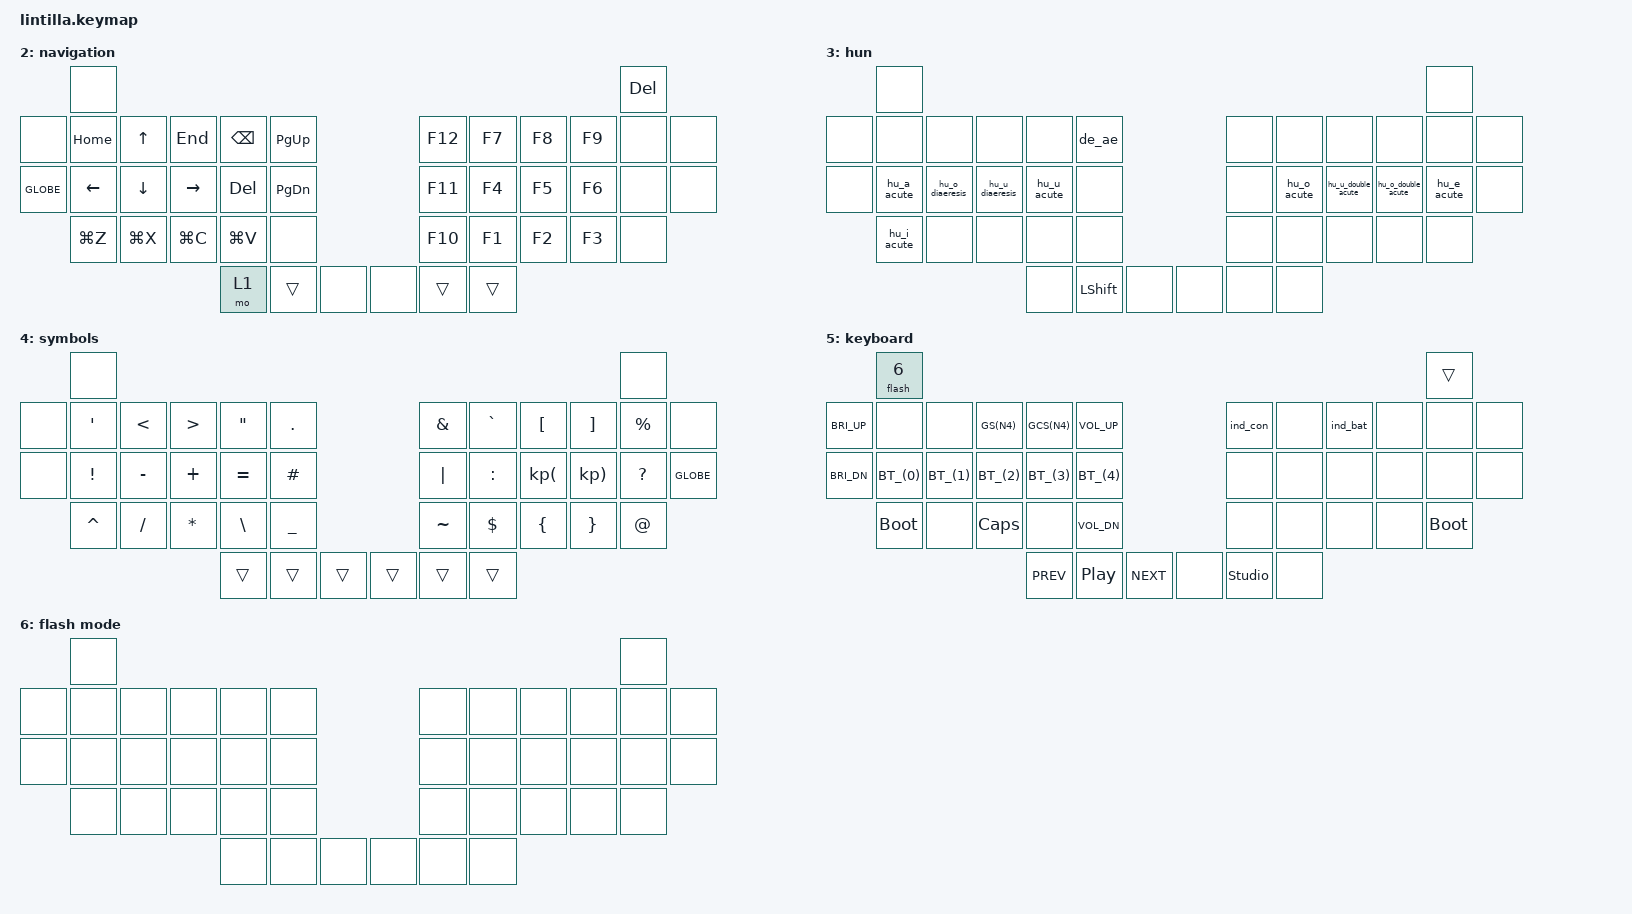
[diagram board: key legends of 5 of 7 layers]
#include <behaviors.dtsi>
#include <dt-bindings/zmk/bt.h>
#include <dt-bindings/zmk/keys.h>
#include <dt-bindings/zmk/outputs.h>
#include <behaviors/rgbled_widget.dtsi>

#include "lintilla_combos.dtsi"
#define HOST_OS 1
#include "zmk-helpers/helper.h"

#include "zmk-helpers/unicode-chars/german.dtsi"


// Multiple mods
#define GS(key) &kp LG(LS(key))
#define GCS(key) &kp LG(LC(LS(key)))
#define HYPR(key) &kp LG(LA(LC(LS(key))))

// Shortcuts for home row mods
#define LGlb &hml GLOBE
#define LSft &hml LSHFT
#define LCtl &hml LCTRL
#define Opt  &hml LALT
#define LCmd &hml LGUI

#define RGlb &hmr GLOBE
#define RSft &hmr LSHFT
#define RCtl &hmr LCTRL
#define RCmd &hmr LGUI
#define Alt  &hmr RALT

ZMK_UNICODE_PAIR(hu_a_acute,        N0, N0,  E, N1,  N0, N0,  C, N1) // á/Á
ZMK_UNICODE_PAIR(hu_e_acute,        N0, N0,  E, N9,  N0, N0,  C, N9) // é/É
ZMK_UNICODE_PAIR(hu_i_acute,        N0, N0,  E,  D,  N0, N0,  C,  D) // í/Í
ZMK_UNICODE_PAIR(hu_o_acute,        N0, N0,  F, N3,  N0, N0,  D, N3) // ó/Ó
ZMK_UNICODE_PAIR(hu_o_diaeresis,    N0, N0,  F, N6,  N0, N0,  D, N6) // ö/Ö
ZMK_UNICODE_PAIR(hu_o_double_acute, N0, N1, N5, N1,  N0, N1, N5, N0) // ő/Ő
ZMK_UNICODE_PAIR(hu_u_acute,        N0, N0,  F,  A,  N0, N0,  D,  A) // ú/Ú
ZMK_UNICODE_PAIR(hu_u_diaeresis,    N0, N0,  F,  C,  N0, N0,  D,  C) // ü/Ü
ZMK_UNICODE_PAIR(hu_u_double_acute, N0, N1, N7, N1,  N0, N1, N7, N0) // ű/Ű

#define KEYS_L 0 2 3  4  5  6  7 14 15 16 17 18 19 26 27 28 29 30
#define KEYS_R 1 8 9 10 11 12 13 20 21 22 23 24 25 31 32 33 34 35
#define THUMBS 36 37 38 39 40 41

// Magic bluetooth button
#define BT_(btnum) &bt_key btnum btnum

/ {
    behaviors {
        bt_key: magic_bluetooth_key {
            compatible = "zmk,behavior-hold-tap";
            #binding-cells = <2>;
            flavor = "tap-preferred";
            tapping-term-ms = <500>;
            bindings = <&bt_clr>, <&bt_sel>;
        };

        hml: homerow_mod_left {
            compatible = "zmk,behavior-hold-tap";
            #binding-cells = <2>;
            tapping-term-ms = <200>;
            require-prior-idle-ms = <150>;
            quick-tap-ms = <175>;
            flavor = "balanced";
            hold-trigger-key-positions = <KEYS_R THUMBS>;
            hold-trigger-on-release;
            bindings = <&kp>, <&kp>;
        };

        hmr: homerow_mod_right {
            compatible = "zmk,behavior-hold-tap";
            #binding-cells = <2>;
            tapping-term-ms = <200>;
            require-prior-idle-ms = <150>;
            quick-tap-ms = <175>;
            flavor = "balanced";
            hold-trigger-key-positions = <KEYS_L THUMBS>;
            hold-trigger-on-release;
            bindings = <&kp>, <&kp>;
        };

        lp_mc: launch_pad_mission_control {
            compatible = "zmk,behavior-tap-dance";
            #binding-cells = <0>;
            tapping-term-ms = <200>;
            bindings = <HYPR(N4)>, <&kp LC(UP)>;
        };

        lsscw: layer_sticky_shift_caps_word {
            compatible = "zmk,behavior-hold-tap";
            #binding-cells = <2>;
            flavor = "balanced";
            tapping-term-ms = <200>;
            bindings = <&mo>, <&sscw>;
        };

        mcs: mod_comma_semi {
            compatible = "zmk,behavior-mod-morph";
            #binding-cells = <0>;
            bindings = <&kp COMMA>, <&kp SEMI>;
            mods = <(MOD_LSFT|MOD_RSFT)>;
        };

        mdc: mod_dot_colon {
            compatible = "zmk,behavior-mod-morph";
            #binding-cells = <0>;
            bindings = <&kp DOT>, <&kp COLON>;
            mods = <(MOD_LSFT|MOD_RSFT)>;
        };

        msb: mod_slash_back {
            compatible = "zmk,behavior-mod-morph";
            #binding-cells = <0>;
            bindings = <&kp SLASH>, <&kp BACKSLASH>;
            mods = <(MOD_LSFT|MOD_RSFT)>;
        };

        sscw: sticky_shift_caps_word {
            compatible = "zmk,behavior-mod-morph";
            #binding-cells = <0>;
            bindings = <&sk LSHIFT>, <&caps_word>;
            mods = <(MOD_LSFT|MOD_RSFT)>;
        };
    };

    macros {
        bt_clr: bluetooth_clear {
            compatible = "zmk,behavior-macro-one-param";
            #binding-cells = <1>;
            bindings = <&macro_param_1to1 &bt_sel MACRO_PLACEHOLDER>, <&bt BT_CLR>;
        };

        bt_sel: bluetooth_select {
            compatible = "zmk,behavior-macro-one-param";
            #binding-cells = <1>;
            bindings = <&out OUT_BLE>, <&macro_param_1to2 &bt BT_SEL MACRO_PLACEHOLDER>;
        };

        flash: dongle_bootloader {
            compatible = "zmk,behavior-macro-one-param";
            #binding-cells = <1>;
            bindings = <&macro_param_1to1 &to MACRO_PLACEHOLDER>, <&bootloader>;
        };

        tmsw: tmux_switch {
            compatible = "zmk,behavior-macro-one-param";
            #binding-cells = <1>;
            bindings = <&kp LC(B) &macro_param_1to1 &kp MACRO_PLACEHOLDER>;
        };
    };



    keymap {
        compatible = "zmk,keymap";

        qwerty {
//                       ┏━━━━━━━━━━━━━━━━━━━━━━━━━┓
            display-name = "Qwerty"                ; // 0
//                       ┗━━━━━━━━━━━━━━━━━━━━━━━━━┛
            bindings = <
//         ┏━━━━━━━┓                                                                                          ┏━━━━━━━┓
//         ┃LAUNCHP┃                                                                                          ┃ MUTE  ┃
            &lp_mc                                                                                          &lt 5 K_MUTE
//         ┃MISSION┃                                                                                          ┃ keybd ┃
// ┏━━━━━━━╋━━━━━━━╋━━━━━━━┳━━━━━━━┳━━━━━━━┳━━━━━━━┓                          ┏━━━━━━━┳━━━━━━━┳━━━━━━━┳━━━━━━━╋━━━━━━━╋━━━━━━━┓
// ┃ Repeat┃   Q   ┃   W   ┃   E   ┃   R   ┃   T   ┃                          ┃   Z   ┃   U   ┃   I   ┃   O   ┃   P   ┃  HUN  ┃
 &key_repeat &kp Q   &kp W   &kp E   &kp R   &kp T                              &kp Z   &kp U   &kp I   &kp O   &kp P   &sl 3
// ┣━━━━━━━╋━━━━━━━╋━━━━━━━╋━━━━━━━╋━━━━━━━╋━━━━━━━┫                          ┣━━━━━━━╋━━━━━━━╋━━━━━━━╋━━━━━━━╋━━━━━━━╋━━━━━━━┫
// ┃  TAB  ┃   A   ┃   S   ┃   D   ┃   F   ┃   G   ┃                          ┃   H   ┃   J   ┃   K   ┃   L   ┃  ; "  ┃RETURN ┃
  LGlb TAB  LCmd A   Opt S   LCtl D   LSft F  &kp G                            &kp H   RSft J   RCtl K   Alt L  RCmd SEMI &lt 3 RET
// ┃ Globe ┃  Cmd  ┃  Opt  ┃  Ctrl ┃ Shift ┃       ┃                          ┃ R Alt ┃ Shift ┃  Ctrl ┃ RAlt  ┃  Cmd  ┃ Globe ┃
// ┗━━━━━━━╋━━━━━━━╋━━━━━━━╋━━━━━━━╋━━━━━━━╋━━━━━━━┫                          ┣━━━━━━━╋━━━━━━━╋━━━━━━━╋━━━━━━━╋━━━━━━━╋━━━━━━━┛
//         ┃   Y   ┃   X   ┃   C   ┃   V   ┃   B   ┃                          ┃   N   ┃   M   ┃  , ;  ┃  . :  ┃  / \  ┃
             &kp Y   &kp X   &kp C   &kp V   &kp B                              &kp N   &kp M   &mcs    &mdc    &msb
//         ┗━━━━━━━┻━━━━━━━┻━━━━━━━┻━━━┳━━━┻━━━┳━━━┻━━━┳━━━━━━━┓  ┏━━━━━━━┳━━━┻━━━┳━━━┻━━━┳━━━┻━━━━━━━┻━━━━━━━┻━━━━━━━┛
//                                     ┃  ESC  ┃ SPACE ┃ { TAB ┃  ┃ } RET ┃ BKSPC ┃ StSft ┃
                                    &kp ESC &lt 4 SPC &lt 1 TAB   &lt 2 RET &kp BSPC &lsscw 3 0
//                                     ┗━━━━━━━┫  sym  ┣━━━━━━━┛  ┗━━━━━━━┫  sym  ┣━━━━━━━┛
//                                             ┗━━━━━━━┛                  ┗━━━━━━━┛
            >;
        };

        num {
//                       ┏━━━━━━━━━━━━━━━━━━━━━━━━━┓
            display-name = "numpad"                ; // 1
//                       ┗━━━━━━━━━━━━━━━━━━━━━━━━━┛
            bindings = <
//         ┏━━━━━━━┓                                                                                          ┏━━━━━━━┓
//         ┃       ┃                                                                                          ┃  DEL  ┃
             &none                                                                                             &kp DEL
// ┏━━━━━━━╋━━━━━━━╋━━━━━━━┳━━━━━━━┳━━━━━━━┳━━━━━━━┓                          ┏━━━━━━━┳━━━━━━━┳━━━━━━━┳━━━━━━━╋━━━━━━━╋━━━━━━━┓
// ┃       ┃       ┃       ┃       ┃       ┃       ┃                          ┃   /   ┃   7   ┃   8   ┃   9   ┃   -   ┃ BKSPC ┃
     &none   &none   &none   &none   &none   &none                            &kp SLASH &kp N7 &kp N8  &kp N9 &kp MINUS &kp BSPC
// ┣━━━━━━━╋━━━━━━━╋━━━━━━━╋━━━━━━━╋━━━━━━━╋━━━━━━━┫                          ┣━━━━━━━╋━━━━━━━╋━━━━━━━╋━━━━━━━╋━━━━━━━╋━━━━━━━┫
// ┃       ┃ CtrlA ┃       ┃ CtrlD ┃       ┃       ┃                          ┃   *   ┃   4   ┃   5   ┃   6   ┃   +   ┃RETURN ┃
&kp GLOBE  LCmd A   Opt S   LCtl D   LSft F  &trans                       &kp STAR &kp N4  &kp N5  &kp N6 &kp PLUS &kp RET
// ┃ Globe ┃ Shift ┃ Ctrl  ┃  Opt  ┃  Cmd  ┃       ┃                          ┃       ┃       ┃       ┃       ┃       ┃       ┃
// ┗━━━━━━━╋━━━━━━━╋━━━━━━━╋━━━━━━━╋━━━━━━━╋━━━━━━━┫                          ┣━━━━━━━╋━━━━━━━╋━━━━━━━╋━━━━━━━╋━━━━━━━╋━━━━━━━┛
//         ┃ CtrlZ ┃ CtrlX ┃ CtrlC ┃ CtrlV ┃       ┃                          ┃   :   ┃   1   ┃   2   ┃   3   ┃   0   ┃
         &kp LC(Z) &kp LC(X) &kp LC(C) &kp LC(V) &none                        &kp COLON &kp N1 &kp N2  &kp N3 &kp N0
//         ┗━━━━━━━┻━━━━━━━┻━━━━━━━┻━━━┳━━━┻━━━┳━━━┻━━━┳━━━━━━━┓  ┏━━━━━━━┳━━━┻━━━┳━━━┻━━━┳━━━┻━━━━━━━┻━━━━━━━┻━━━━━━━┛
//                                     ┃ ##### ┃       ┃       ┃  ┃   .   ┃ SPACE ┃   0   ┃
                                         &trans  &mo 2   &none    &kp COMMA &kp SPC &kp N0
//                                     ┗━━━━━━━┫  fn   ┣━━━━━━━┛  ┗━━━━━━━┫       ┣━━━━━━━┛
//                                             ┗━━━━━━━┛                  ┗━━━━━━━┛
            >;
        };

        nav {
//                       ┏━━━━━━━━━━━━━━━━━━━━━━━━━┓
            display-name = "navigation"            ; // 2
//                       ┗━━━━━━━━━━━━━━━━━━━━━━━━━┛
            bindings = <
//         ┏━━━━━━━┓                                                                                          ┏━━━━━━━┓
//         ┃       ┃                                                                                          ┃  DEL  ┃
             &none                                                                                             &kp DEL
// ┏━━━━━━━╋━━━━━━━╋━━━━━━━┳━━━━━━━┳━━━━━━━┳━━━━━━━┓                          ┏━━━━━━━┳━━━━━━━┳━━━━━━━┳━━━━━━━╋━━━━━━━╋━━━━━━━┓
// ┃       ┃ Home  ┃  Up   ┃  End  ┃ BKSPC ┃ Pg Up ┃                          ┃  F12  ┃  F7   ┃  F8   ┃  F9   ┃       ┃       ┃
     &none &kp HOME &kp UP &kp END &kp BSPC &kp PG_UP                          &kp F12  &kp F7  &kp F8  &kp F9  &none   &none
// ┣━━━━━━━╋━━━━━━━╋━━━━━━━╋━━━━━━━╋━━━━━━━╋━━━━━━━┫                          ┣━━━━━━━╋━━━━━━━╋━━━━━━━╋━━━━━━━╋━━━━━━━╋━━━━━━━┫
// ┃       ┃ Left  ┃ Down  ┃ Right ┃  DEL  ┃ Pg Dn ┃                          ┃  F11  ┃  F4   ┃  F5   ┃  F6   ┃       ┃       ┃
&kp GLOBE &kp LEFT &kp DOWN &kp RIGHT &kp DEL &kp PG_DN                        &kp F11  &kp F4  &kp F5  &kp F6  &none   &none
// ┃ Globe ┃       ┃       ┃       ┃       ┃       ┃                          ┃       ┃       ┃       ┃       ┃       ┃       ┃
// ┗━━━━━━━╋━━━━━━━╋━━━━━━━╋━━━━━━━╋━━━━━━━╋━━━━━━━┫                          ┣━━━━━━━╋━━━━━━━╋━━━━━━━╋━━━━━━━╋━━━━━━━╋━━━━━━━┛
//         ┃ Cmd Z ┃ Cmd X ┃ Cmd C ┃ Cmd V ┃       ┃                          ┃  F10  ┃  F1   ┃  F2   ┃  F3   ┃       ┃
         &kp LG(Z) &kp LG(X) &kp LG(C) &kp LG(V) &none                         &kp F10  &kp F1  &kp F2  &kp F3  &none
//         ┗━━━━━━━┻━━━━━━━┻━━━━━━━┻━━━┳━━━┻━━━┳━━━┻━━━┳━━━━━━━┓  ┏━━━━━━━┳━━━┻━━━┳━━━┻━━━┳━━━┻━━━━━━━┻━━━━━━━┻━━━━━━━┛
//                                     ┃  fn   ┃ ##### ┃       ┃  ┃       ┃ ##### ┃ ##### ┃
                                         &mo 1   &trans  &none      &none  &trans   &trans
//                                     ┗━━━━━━━┫       ┣━━━━━━━┛  ┗━━━━━━━┫       ┣━━━━━━━┛
//                                             ┗━━━━━━━┛                  ┗━━━━━━━┛
            >;
        };

        hun {
//                       ┏━━━━━━━━━━━━━━━━━━━━━━━━━┓
            display-name = "hun"                   ; // 3
//                       ┗━━━━━━━━━━━━━━━━━━━━━━━━━┛
            bindings = <
//         ┏━━━━━━━┓                                                                                          ┏━━━━━━━┓
//         ┃       ┃                                                                                          ┃       ┃
             &none                                                                                              &none
// ┏━━━━━━━╋━━━━━━━╋━━━━━━━┳━━━━━━━┳━━━━━━━┳━━━━━━━┓                          ┏━━━━━━━┳━━━━━━━┳━━━━━━━┳━━━━━━━╋━━━━━━━╋━━━━━━━┓
// ┃       ┃       ┃       ┃       ┃       ┃       ┃                          ┃       ┃       ┃       ┃       ┃       ┃       ┃
     &none   &none   &none   &none   &none   &de_ae                              &none   &none   &none   &none   &none   &none
// ┣━━━━━━━╋━━━━━━━╋━━━━━━━╋━━━━━━━╋━━━━━━━╋━━━━━━━┫                          ┣━━━━━━━╋━━━━━━━╋━━━━━━━╋━━━━━━━╋━━━━━━━╋━━━━━━━┫
// ┃       ┃   á   ┃   ö   ┃   ü   ┃   ú   ┃       ┃                          ┃       ┃   ó   ┃   ű   ┃   ő   ┃   é   ┃       ┃
&none &hu_a_acute &hu_o_diaeresis &hu_u_diaeresis &hu_u_acute &none             &none &hu_o_acute &hu_u_double_acute &hu_o_double_acute &hu_e_acute   &none
// ┗━━━━━━━╋━━━━━━━╋━━━━━━━╋━━━━━━━╋━━━━━━━╋━━━━━━━┫                          ┣━━━━━━━╋━━━━━━━╋━━━━━━━╋━━━━━━━╋━━━━━━━╋━━━━━━━┛
//         ┃   í   ┃       ┃       ┃       ┃       ┃                          ┃       ┃       ┃       ┃       ┃       ┃
         &hu_i_acute &none   &none   &none   &none                              &none   &none   &none   &none   &none
//         ┗━━━━━━━┻━━━━━━━┻━━━━━━━┻━━━┳━━━┻━━━┳━━━┻━━━┳━━━━━━━┓  ┏━━━━━━━┳━━━┻━━━┳━━━┻━━━┳━━━┻━━━━━━━┻━━━━━━━┻━━━━━━━┛
//                                     ┃       ┃       ┃       ┃  ┃       ┃       ┃       ┃
                                        &none  &kp LSHIFT &none     &none   &none   &none
//                                     ┗━━━━━━━┫       ┣━━━━━━━┛  ┗━━━━━━━┫       ┣━━━━━━━┛
//                                             ┗━━━━━━━┛                  ┗━━━━━━━┛
            >;
        };

        sym {
//                       ┏━━━━━━━━━━━━━━━━━━━━━━━━━┓
            display-name = "symbols"               ; // 4
//                       ┗━━━━━━━━━━━━━━━━━━━━━━━━━┛
            bindings = <
//         ┏━━━━━━━┓                                                                                          ┏━━━━━━━┓
//         ┃       ┃                                                                                          ┃       ┃
             &none                                                                                              &none
// ┏━━━━━━━╋━━━━━━━╋━━━━━━━┳━━━━━━━┳━━━━━━━┳━━━━━━━┓                          ┏━━━━━━━┳━━━━━━━┳━━━━━━━┳━━━━━━━╋━━━━━━━╋━━━━━━━┓
// ┃       ┃   '   ┃   <   ┃   >   ┃   "   ┃   .   ┃                          ┃   &   ┃   `   ┃   [   ┃   ]   ┃   %   ┃       ┃
     &none &kp APOS &kp LT &kp GT &kp DQT &kp DOT                         &kp AMPS &kp GRAVE &kp LBKT  &kp RBKT  &kp PRCNT &none
// ┣━━━━━━━╋━━━━━━━╋━━━━━━━╋━━━━━━━╋━━━━━━━╋━━━━━━━┫                          ┣━━━━━━━╋━━━━━━━╋━━━━━━━╋━━━━━━━╋━━━━━━━╋━━━━━━━┫
// ┃       ┃   !   ┃   -   ┃   +   ┃   =   ┃   #   ┃                          ┃   |   ┃   :   ┃   (   ┃   )   ┃   ?   ┃ Globe ┃
&none &kp EXCL &kp MINUS &kp PLUS &kp EQUAL &kp HASH                      &kp PIPE &kp COLON &kp KP_LPAR &kp KP_RPAR &kp QMARK &kp GLOBE
// ┗━━━━━━━╋━━━━━━━╋━━━━━━━╋━━━━━━━╋━━━━━━━╋━━━━━━━┫                          ┣━━━━━━━╋━━━━━━━╋━━━━━━━╋━━━━━━━╋━━━━━━━╋━━━━━━━┛
//         ┃   ^   ┃   /   ┃   *   ┃   \   ┃   _   ┃                          ┃   ~   ┃   $   ┃   {   ┃   }   ┃   @   ┃
        &kp CARET &kp FSLH &kp STAR &kp BSLH &kp UNDER                    &kp TILDE &kp DLLR &kp LBRC &kp RBRC &kp AT
//         ┗━━━━━━━┻━━━━━━━┻━━━━━━━┻━━━┳━━━┻━━━┳━━━┻━━━┳━━━━━━━┓  ┏━━━━━━━┳━━━┻━━━┳━━━┻━━━┳━━━┻━━━━━━━┻━━━━━━━┻━━━━━━━┛
//                                     ┃ ##### ┃ ##### ┃ ##### ┃  ┃ ##### ┃ ##### ┃ ##### ┃
                                         &trans  &trans  &trans     &trans  &trans  &trans
//                                     ┗━━━━━━━┫       ┣━━━━━━━┛  ┗━━━━━━━┫       ┣━━━━━━━┛
//                                             ┗━━━━━━━┛                  ┗━━━━━━━┛
            >;
        };

        keybd {
//                       ┏━━━━━━━━━━━━━━━━━━━━━━━━━┓
            display-name = "keyboard"              ; // 5
//                       ┗━━━━━━━━━━━━━━━━━━━━━━━━━┛
            bindings = <
//         ┏━━━━━━━┓                                                                                          ┏━━━━━━━┓
//         ┃ dongle┃                                                                                          ┃ ##### ┃
           &flash 6                                                                                             &trans
// ┏━━━━━━━╋━━━━━━━╋━━━━━━━┳━━━━━━━┳━━━━━━━┳━━━━━━━┓                          ┏━━━━━━━┳━━━━━━━┳━━━━━━━┳━━━━━━━╋━━━━━━━╋━━━━━━━┓
// ┃ brt + ┃       ┃       ┃scrnsht┃scrn cp┃ vol + ┃                          ┃con led┃       ┃bat led┃       ┃       ┃       ┃
&kp C_BRI_UP &none   &none  GS(N4) GCS(N4) &kp C_VOL_UP                       &ind_con  &none &ind_bat  &none   &none   &none
// ┣━━━━━━━╋━━━━━━━╋━━━━━━━╋━━━━━━━╋━━━━━━━╋━━━━━━━┫                          ┣━━━━━━━╋━━━━━━━╋━━━━━━━╋━━━━━━━╋━━━━━━━╋━━━━━━━┫
// ┃ brt - ┃  BT1  ┃  BT2  ┃  BT3  ┃  BT4  ┃  BT5  ┃                          ┃       ┃       ┃       ┃       ┃       ┃       ┃
&kp C_BRI_DN BT_(0)  BT_(1)  BT_(2)  BT_(3)  BT_(4)                             &none   &none   &none   &none   &none   &none
// ┗━━━━━━━╋━━━━━━━╋━━━━━━━╋━━━━━━━╋━━━━━━━╋━━━━━━━┫                          ┣━━━━━━━╋━━━━━━━╋━━━━━━━╋━━━━━━━╋━━━━━━━╋━━━━━━━┛
//         ┃ flash ┃       ┃caps lk┃       ┃ vol - ┃                          ┃       ┃       ┃       ┃       ┃ flash ┃
        &bootloader &none &kp CAPS &none &kp C_VOL_DN                           &none   &none   &none   &none &bootloader
//         ┗━━━━━━━┻━━━━━━━┻━━━━━━━┻━━━┳━━━┻━━━┳━━━┻━━━┳━━━━━━━┓  ┏━━━━━━━┳━━━┻━━━┳━━━┻━━━┳━━━┻━━━━━━━┻━━━━━━━┻━━━━━━━┛
//                                     ┃ prev  ┃ play  ┃ next  ┃  ┃       ┃studio ┃       ┃
                                   &kp C_PREV &kp C_PP &kp C_NEXT &none &studio_unlock &none
//                                     ┗━━━━━━━┫       ┣━━━━━━━┛  ┗━━━━━━━┫ unlock┣━━━━━━━┛
//                                             ┗━━━━━━━┛                  ┗━━━━━━━┛
            >;
        };

        flash {
//                       ┏━━━━━━━━━━━━━━━━━━━━━━━━━┓
            display-name = "flash mode"            ; // 6
//                       ┗━━━━━━━━━━━━━━━━━━━━━━━━━┛
            bindings = <
//         ┏━━━━━━━┓                                                                                          ┏━━━━━━━┓
//         ┃       ┃                                                                                          ┃       ┃
             &none                                                                                              &none
// ┏━━━━━━━╋━━━━━━━╋━━━━━━━┳━━━━━━━┳━━━━━━━┳━━━━━━━┓                          ┏━━━━━━━┳━━━━━━━┳━━━━━━━┳━━━━━━━╋━━━━━━━╋━━━━━━━┓
// ┃       ┃       ┃       ┃       ┃       ┃       ┃                          ┃       ┃       ┃       ┃       ┃       ┃       ┃
     &none   &none   &none   &none   &none   &none                              &none   &none   &none   &none   &none   &none
// ┣━━━━━━━╋━━━━━━━╋━━━━━━━╋━━━━━━━╋━━━━━━━╋━━━━━━━┫                          ┣━━━━━━━╋━━━━━━━╋━━━━━━━╋━━━━━━━╋━━━━━━━╋━━━━━━━┫
// ┃       ┃       ┃       ┃       ┃       ┃       ┃                          ┃       ┃       ┃       ┃       ┃       ┃       ┃
     &none   &none   &none   &none   &none   &none                              &none   &none   &none   &none   &none   &none
// ┗━━━━━━━╋━━━━━━━╋━━━━━━━╋━━━━━━━╋━━━━━━━╋━━━━━━━┫                          ┣━━━━━━━╋━━━━━━━╋━━━━━━━╋━━━━━━━╋━━━━━━━╋━━━━━━━┛
//         ┃       ┃       ┃       ┃       ┃       ┃                          ┃       ┃       ┃       ┃       ┃       ┃
             &none   &none   &none   &none   &none                              &none   &none   &none   &none   &none
//         ┗━━━━━━━┻━━━━━━━┻━━━━━━━┻━━━┳━━━┻━━━┳━━━┻━━━┳━━━━━━━┓  ┏━━━━━━━┳━━━┻━━━┳━━━┻━━━┳━━━┻━━━━━━━┻━━━━━━━┻━━━━━━━┛
//                                     ┃       ┃       ┃       ┃  ┃       ┃       ┃       ┃
                                         &none   &none   &none      &none   &none   &none
//                                     ┗━━━━━━━┫       ┣━━━━━━━┛  ┗━━━━━━━┫       ┣━━━━━━━┛
//                                             ┗━━━━━━━┛                  ┗━━━━━━━┛
            >;
        };

        // Extra empty layers for ZMK Studio

        layer7 {
            status = "reserved";
        };

        layer8 {
            status = "reserved";
        };

        layer9 {
            status = "reserved";
        };

        layer10 {
            status = "reserved";
        };

        layer11 {
            status = "reserved";
        };

        layer12 {
            status = "reserved";
        };

        layer13 {
            status = "reserved";
        };

        layer14 {
            status = "reserved";
        };

        layer15 {
            status = "reserved";
        };
    };
};

// vim: expandtab softtabstop=4 shiftwidth=4 filetype=dts
